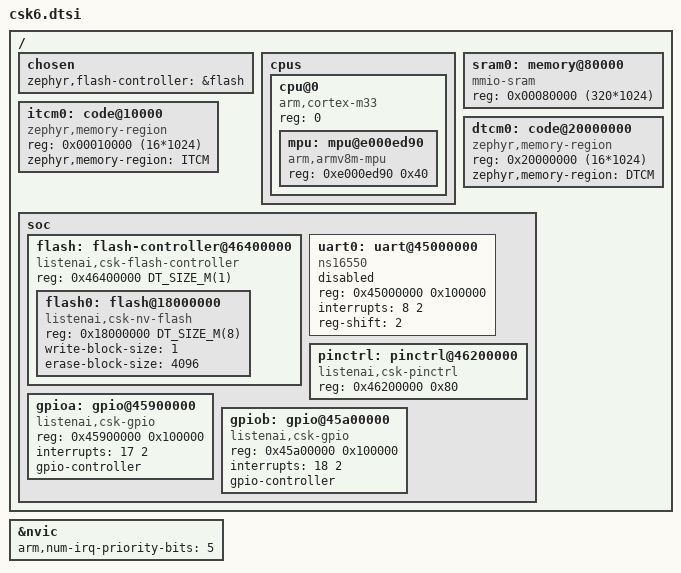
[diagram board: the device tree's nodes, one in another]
/* SPDX-License-Identifier: Apache-2.0 */

#include <mem.h>
#include <arm/armv8-m.dtsi>

/ {
	chosen {
		zephyr,flash-controller = &flash;
	};
	cpus {
		#address-cells = <1>;
		#size-cells = <0>;

		cpu@0 {
			device_type = "cpu";
			compatible = "arm,cortex-m33";
			reg = <0>;
			#address-cells = <1>;
			#size-cells = <1>;

			mpu: mpu@e000ed90 {
				compatible = "arm,armv8m-mpu";
				reg = <0xe000ed90 0x40>;
			};
		};
	};

	sram0: memory@80000 {
		compatible = "mmio-sram";
		reg = <0x00080000 (320*1024)>;
	};

	itcm0: code@10000 {
		compatible = "zephyr,memory-region";
		reg = <0x00010000 (16*1024)>;
		zephyr,memory-region = "ITCM";
	};

	dtcm0: code@20000000 {
		compatible = "zephyr,memory-region";
		reg = <0x20000000 (16*1024)>;
		zephyr,memory-region = "DTCM";
	};

	soc {
		flash: flash-controller@46400000 {
			compatible = "listenai,csk-flash-controller";
			reg = <0x46400000 DT_SIZE_M(1)>;
			#address-cells = <1>;
			#size-cells = <1>;

			flash0: flash@18000000 {
				compatible = "listenai,csk-nv-flash","soc-nv-flash";
				reg = <0x18000000 DT_SIZE_M(8)>;
				write-block-size = <1>;
				erase-block-size = <4096>;
			};
		};

		uart0: uart@45000000 {
			compatible = "ns16550";
			reg = <0x45000000 0x100000>;
			interrupts = <8 2>;
			reg-shift = <2>;
			status = "disabled";
		};

		pinctrl: pinctrl@46200000{
			compatible = "listenai,csk-pinctrl";
			reg = <0x46200000 0x80>;
			#address-cells = <1>;
			#size-cells = <1>;
			status = "okay";
		};

		gpioa: gpio@45900000 {
			compatible = "listenai,csk-gpio";
			reg = <0x45900000 0x100000>;
			interrupts = <17 2>;
			gpio-controller;
			#gpio-cells = <2>;
		};

		gpiob: gpio@45a00000 {
			compatible = "listenai,csk-gpio";
			reg = <0x45a00000 0x100000>;
			interrupts = <18 2>;
			gpio-controller;
			#gpio-cells = <2>;
		};
	};
};

&nvic {
	arm,num-irq-priority-bits = <5>;
};
